# STM32F070x6 register map
File version: 1.0
Registers are 32-bit, read-write, reset 0x0 unless marked. A register's access mark holds for its fields unless they carry their own. Offsets are from the block's base; lines under a group give offsets from that group; [hi:lo] are bit positions; {n}, {i} and the like mark numbered series; 'fields as' and 'values as' point back to an identical list; <NAME> marks a mode.

## Memory map
0x1FFFF800 OB — Option Bytes Registers
0x40000400 TIM3 — TIM
0x40002000 TIM14 — TIM
0x40002800 RTC — Real-Time Clock
0x40002C00 WWDG — Window WATCHDOG
0x40003000 IWDG — Independent WATCHDOG
0x40004400 USART2 — Universal Synchronous Asynchronous Receiver Transmitter
0x40005400 I2C1 — Inter-integrated Circuit Interface
0x40005C00 USB — Universal Serial Bus Full Speed Device
0x40007000 PWR — Power Control
0x40010000 SYSCFG — SysTem Configuration
0x40010400 EXTI — External Interrupt/Event Controller
0x40012400 ADC1 — Analog to Digital Converter
0x40012708 ADC
0x40012C00 TIM1 — TIM
0x40013000 SPI1 — Serial Peripheral Interface
0x40013800 USART1 — Universal Synchronous Asynchronous Receiver Transmitter
0x40014400 TIM16 — TIM
0x40014800 TIM17 — TIM
0x40015800 DBGMCU — Debug MCU
0x40020000 DMA1
0x40021000 RCC — Reset and Clock Control
0x40022000 FLASH — FLASH Registers
0x40023000 CRC — CRC calculation unit
0x48000000 GPIOA — General Purpose I/O
0x48000400 GPIOB — General Purpose I/O
0x48000800 GPIOC — General Purpose I/O
0x48000C00 GPIOD — General Purpose I/O
0x48001400 GPIOF — General Purpose I/O

## Interrupts
0 WWDG — Window WatchDog Interrupt
2 RTC — RTC Interrupt through EXTI Lines 17, 19 and 20
3 FLASH — FLASH global Interrupt
4 RCC — RCC global Interrupt
5 EXTI0_1 (EXTI) — EXTI Line 0 and 1 Interrupt
6 EXTI2_3 (EXTI) — EXTI Line 2 and 3 Interrupt
7 EXTI4_15 (EXTI) — EXTI Line 4 to 15 Interrupt
9 DMA1_Channel1 (DMA1) — DMA1 Channel 1 Interrupt
10 DMA1_Channel2_3 (DMA1) — DMA1 Channel 2 and Channel 3 Interrupt
11 DMA1_Channel4_5 (DMA1) — DMA1 Channel 4 and Channel 5 Interrupt
12 ADC1 — ADC1 Interrupt
13 TIM1_BRK_UP_TRG_COM (TIM1) — TIM1 Break, Update, Trigger and Commutation Interrupt
14 TIM1_CC (TIM1) — TIM1 Capture Compare Interrupt
16 TIM3 — TIM3 global Interrupt
19 TIM14 — TIM14 global Interrupt
21 TIM16 — TIM16 global Interrupt
22 TIM17 — TIM17 global Interrupt
23 I2C1 — I2C1 Event Interrupt & EXTI Line23 Interrupt (I2C1 wakeup)
25 SPI1 — SPI1 global Interrupt
27 USART1 — USART1 global Interrupt & EXTI Line25 Interrupt (USART1 wakeup)
28 USART2 — USART2 global Interrupt
31 USB — USB global Interrupt & EXTI Line18 Interrupt

## OB — Option Bytes Registers
Base 0x1FFFF800
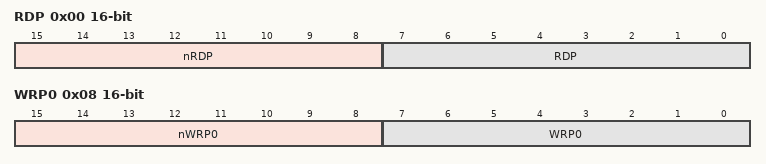
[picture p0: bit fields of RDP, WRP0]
0x00 RDP 16-bit — FLASH option byte Read protection
  [15:8] nRDP — Read protection complemented option byte
  [7:0] RDP — Read protection option byte
0x02 USER 16-bit — FLASH option byte user options
  [31:24] nUSER — User complemented option byte
  [23:16] USER — User option byte
0x04 DATA0 16-bit — User data byte 0 (stored in FLASH_OBR[23:16])
0x06 DATA1 16-bit — User data byte 1 (stored in FLASH_OBR[31:24])
0x08 WRP0 16-bit — FLASH option byte write protection 0
  [15:8] nWRP0 — Flash memory write protection complemented option bytes
  [7:0] WRP0 — Flash memory write protection option bytes

## WWDG — Window WATCHDOG
Base 0x40002C00
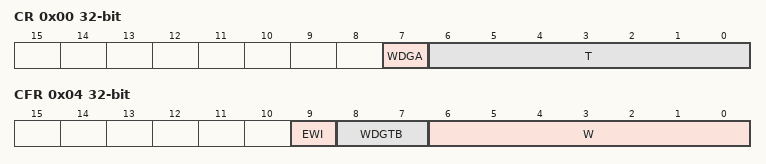
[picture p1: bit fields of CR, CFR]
0x00 CR — WWDG Control register
  [7] WDGA — Activation bit
  [6:0] T — T[6:0] bits (7-Bit counter (MSB to LSB))
0x04 CFR — WWDG Configuration register
  [9] EWI — Early Wakeup Interrupt
  [8:7] WDGTB — WDGTB[1:0] bits (Timer Base)
    0=PRESCALER_1 (WWDG counter clock = (PCLK1/4096)/1); 1=PRESCALER_2 (WWDG counter clock = (PCLK1/4096)/2); 2=PRESCALER_4 (WWDG counter clock = (PCLK1/4096)/4); 3=PRESCALER_8 (WWDG counter clock = (PCLK1/4096)/8)
  [6:0] W — W[6:0] bits (7-bit window value)
0x08 SR — WWDG Status register
  [0] EWIF — Early Wakeup Interrupt Flag

## IWDG — Independent WATCHDOG
Base 0x40003000
0x00 KR — IWDG Key register
  [15:0] KEY — Key value (write only, read 0000h)
0x04 PR — IWDG Prescaler register
  [2:0] PR — PR[2:0] (Prescaler divider)
0x08 RLR — IWDG Reload register
  [11:0] RL — Watchdog counter reload value
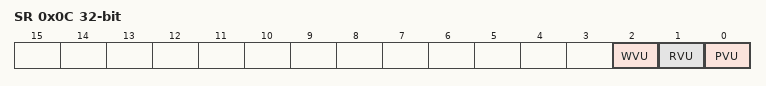
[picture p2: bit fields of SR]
0x0C SR — IWDG Status register
  [2] WVU — Watchdog counter window value update
  [1] RVU — Watchdog counter reload value update
  [0] PVU — Watchdog prescaler value update
0x10 WINR — IWDG Window register
  [11:0] WIN — Watchdog counter window value
